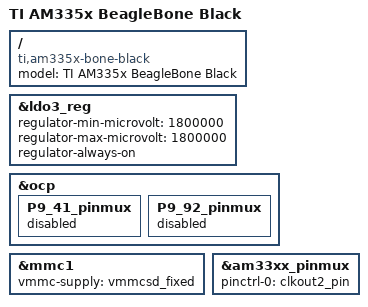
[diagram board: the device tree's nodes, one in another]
/*
 * Copyright (C) 2012 Texas Instruments Incorporated - http://www.ti.com/
 *
 * This program is free software; you can redistribute it and/or modify
 * it under the terms of the GNU General Public License version 2 as
 * published by the Free Software Foundation.
 */
/dts-v1/;

/*
 *	#include "am33xx.dtsi"
 *	#include "am335x-bone-common.dtsi"
 *	#include "am335x-bone-common-pinmux.dtsi"
*/


#include "am335x-bone-both-can.dtsi"
#include "am335x-bone-common-both-can-i2c1-rtc.dtsi"
#include "am335x-bone-common-pinmux-both-can.dtsi"



/ {
	model = "TI AM335x BeagleBone Black";
	compatible = "ti,am335x-bone-black", "ti,am335x-bone", "ti,am33xx";
};

&ldo3_reg {
	regulator-min-microvolt = <1800000>;
	regulator-max-microvolt = <1800000>;
	regulator-always-on;
};

&ocp {
	/* clkout2 */
	P9_41_pinmux {
		status = "disabled";
	};
	/* mmc1 */
	P9_92_pinmux {
		status = "disabled";
	};
};

&mmc1 {
	vmmc-supply = <&vmmcsd_fixed>;
};

&am33xx_pinmux {
	pinctrl-names = "default";
	pinctrl-0 = <&clkout2_pin>;
};

#include "am335x-boneblack-emmc.dtsi"
/* HDMI: with audio */
#include "am335x-boneblack-nxp-hdmi-audio.dtsi"

/* can1: P9_24, P9_26 */
#include "am335x-bone-can1.dtsi"

/* can0: P9_19, P9_20*/
/*Pay special attention, Pins are defined for cape eeprom,
* i2c2 has to be deleted from am335x-bone-common.dtsi or i2c2_pins
* has to be moved to the second pin pair   */
#include "am335x-bone-can0.dtsi"

/* rtc on i2c1  */
#include "am335x-rtc-ds1307.dtsi"
